# STM32L4R9 register map
File version: 2.2
CPU: CM4 r0p1, little endian, MPU, FPU, 4 interrupt priority bits
Registers are 32-bit, read-write, reset 0x0 unless marked. A register's access mark holds for its fields unless they carry their own. Offsets are from the block's base; [hi:lo] are bit positions; {n}, {i} and the like mark numbered series; 'fields as' and 'values as' point back to an identical list.

## DSI — DSI Host
Base 0x40016C00
0x00 DSI_VR ro reset 0x3133302A — DSI Host Version Register
  [31:0] VERSION — Version of the DSI Host
0x04 DSI_CR — DSI Host Control Register
  [0] EN — Enable
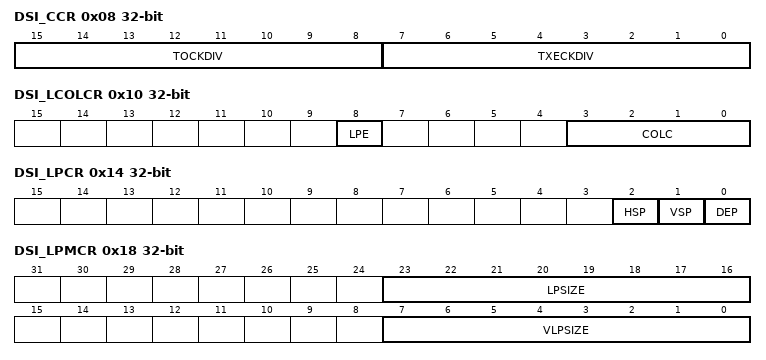
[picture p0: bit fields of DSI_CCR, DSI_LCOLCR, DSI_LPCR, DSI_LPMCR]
0x08 DSI_CCR — DSI HOST Clock Control Register
  [15:8] TOCKDIV — Timeout Clock Division
  [7:0] TXECKDIV — TX Escape Clock Division
0x0C DSI_LVCIDR — DSI Host LTDC VCID Register
  [1:0] VCID — Virtual Channel ID
0x10 DSI_LCOLCR — DSI Host LTDC Color Coding Register
  [8] LPE — Loosely Packet Enable
  [3:0] COLC — Color Coding
0x14 DSI_LPCR — DSI Host LTDC Polarity Configuration Register
  [2] HSP — HSYNC Polarity
  [1] VSP — VSYNC Polarity
  [0] DEP — Data Enable Polarity
0x18 DSI_LPMCR — DSI Host Low-Power mode Configuration Register
  [23:16] LPSIZE — Largest Packet Size
  [7:0] VLPSIZE — VACT Largest Packet Size
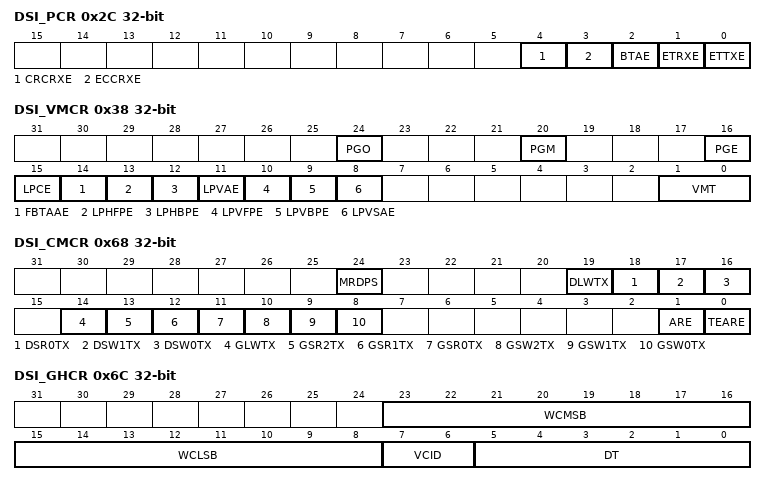
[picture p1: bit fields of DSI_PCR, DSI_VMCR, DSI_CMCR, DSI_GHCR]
0x2C DSI_PCR — DSI Host Protocol Configuration Register
  [4] CRCRXE — CRC Reception Enable
  [3] ECCRXE — ECC Reception Enable
  [2] BTAE — Bus Turn Around Enable
  [1] ETRXE — EoTp Reception Enable
  [0] ETTXE — EoTp Transmission Enable
0x30 DSI_GVCIDR — DSI Host Generic VCID Register
  [1:0] VCID — Virtual Channel ID
0x34 DSI_MCR reset 0x1 — DSI Host mode Configuration Register
  [0] CMDM — Command mode
0x38 DSI_VMCR — DSI Host Video mode Configuration Register
  [24] PGO — Pattern Generator Orientation
  [20] PGM — Pattern Generator mode
  [16] PGE — Pattern Generator Enable
  [15] LPCE — Low-Power Command Enable
  [14] FBTAAE — Frame Bus-Turn-Around Acknowledge Enable
  [13] LPHFPE — Low-Power Horizontal Front-Porch Enable
  [12] LPHBPE — Low-Power Horizontal Back-Porch Enable
  [11] LPVAE — Low-Power Vertical Active Enable
  [10] LPVFPE — Low-power Vertical Front-porch Enable
  [9] LPVBPE — Low-power Vertical Back-Porch Enable
  [8] LPVSAE — Low-Power Vertical Sync Active Enable
  [1:0] VMT — Video mode Type
0x3C DSI_VPCR — DSI Host Video Packet Configuration Register
  [13:0] VPSIZE — Video Packet Size
0x40 DSI_VCCR — DSI Host Video Chunks Configuration Register
  [12:0] NUMC — Number of Chunks
0x44 DSI_VNPCR — DSI Host Video Null Packet Configuration Register
  [12:0] NPSIZE — Null Packet Size
0x48 DSI_VHSACR — DSI Host Video HSA Configuration Register
  [11:0] HSA — Horizontal Synchronism Active duration
0x4C DSI_VHBPCR — DSI Host Video HBP Configuration Register
  [11:0] HBP — Horizontal Back-Porch duration
0x50 DSI_VLCR — DSI Host Video Line Configuration Register
  [14:0] HLINE — Horizontal Line duration
0x54 DSI_VVSACR — DSI Host Video VSA Configuration Register
  [9:0] VSA — Vertical Synchronism Active duration
0x58 DSI_VVBPCR — DSI Host Video VBP Configuration Register
  [9:0] VBP — Vertical Back-Porch duration
0x5C DSI_VVFPCR — DSI Host Video VFP Configuration Register
  [9:0] VFP — Vertical Front-Porch duration
0x60 DSI_VVACR — DSI Host Video VA Configuration Register
  [13:0] VA — Vertical Active duration
0x64 DSI_LCCR — DSI Host LTDC Command Configuration Register
  [15:0] CMDSIZE — Command Size
0x68 DSI_CMCR — DSI Host Command mode Configuration Register
  [24] MRDPS — Maximum Read Packet Size
  [19] DLWTX — DCS Long Write Transmission
  [18] DSR0TX — DCS Short Read Zero parameter Transmission
  [17] DSW1TX — DCS Short Read One parameter Transmission
  [16] DSW0TX — DCS Short Write Zero parameter Transmission
  [14] GLWTX — Generic Long Write Transmission
  [13] GSR2TX — Generic Short Read Two parameters Transmission
  [12] GSR1TX — Generic Short Read One parameters Transmission
  [11] GSR0TX — Generic Short Read Zero parameters Transmission
  [10] GSW2TX — Generic Short Write Two parameters Transmission
  [9] GSW1TX — Generic Short Write One parameters Transmission
  [8] GSW0TX — Generic Short Write Zero parameters Transmission
  [1] ARE — Acknowledge Request Enable
  [0] TEARE — Tearing Effect Acknowledge Request Enable
0x6C DSI_GHCR — DSI Host Generic Header Configuration Register
  [23:16] WCMSB — WordCount MSB
  [15:8] WCLSB — WordCount LSB
  [7:6] VCID — Channel
  [5:0] DT — Type
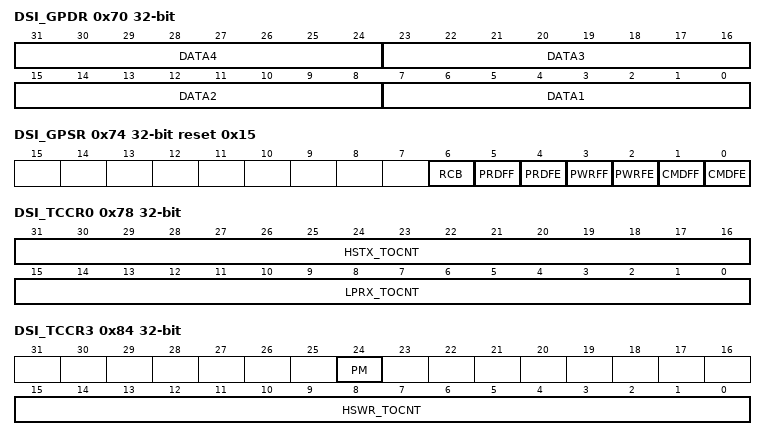
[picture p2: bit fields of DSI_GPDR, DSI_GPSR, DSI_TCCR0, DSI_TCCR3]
0x70 DSI_GPDR — DSI Host Generic Payload Data Register
  [8n-1:8n-8] DATA{n} (n=1..4) — Payload Byte {n}
0x74 DSI_GPSR ro reset 0x15 — DSI Host Generic Packet Status Register
  [6] RCB — Read Command Busy
  [5] PRDFF — Payload Read FIFO Full
  [4] PRDFE — Payload Read FIFO Empty
  [3] PWRFF — Payload Write FIFO Full
  [2] PWRFE — Payload Write FIFO Empty
  [1] CMDFF — Command FIFO Full
  [0] CMDFE — Command FIFO Empty
0x78 DSI_TCCR0 — DSI Host Timeout Counter Configuration Register 0
  [31:16] HSTX_TOCNT — High-Speed Transmission Timeout Counter
  [15:0] LPRX_TOCNT — Low-power Reception Timeout Counter
0x7C DSI_TCCR1 — DSI Host Timeout Counter Configuration Register 1
  [15:0] HSRD_TOCNT — High-Speed Read Timeout Counter
0x80 DSI_TCCR2 — DSI Host Timeout Counter Configuration Register 2
  [15:0] LPRD_TOCNT — Low-Power Read Timeout Counter
0x84 DSI_TCCR3 — DSI Host Timeout Counter Configuration Register 3
  [24] PM — Presp mode
  [15:0] HSWR_TOCNT — High-Speed Write Timeout Counter
0x88 DSI_TCCR4 — DSI Host Timeout Counter Configuration Register 4
  [15:0] LSWR_TOCNT — Low-Power Write Timeout Counter
0x8C DSI_TCCR5 — DSI Host Timeout Counter Configuration Register 5
  [15:0] BTA_TOCNT — Bus-Turn-Around Timeout Counter
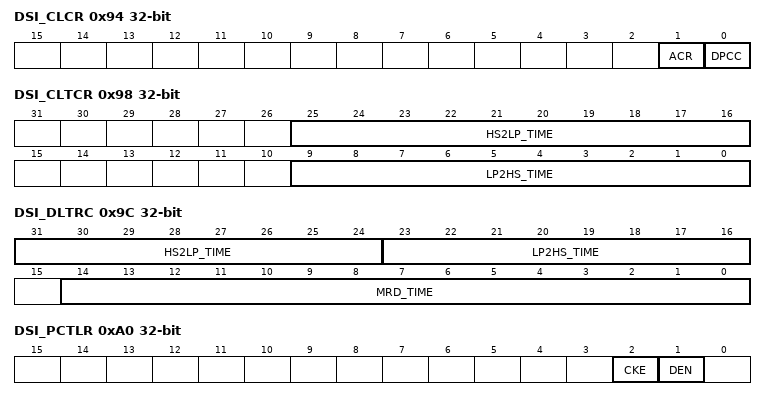
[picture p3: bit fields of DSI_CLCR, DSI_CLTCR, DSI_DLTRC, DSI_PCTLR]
0x94 DSI_CLCR — DSI Host Clock Lane Configuration Register
  [1] ACR — Automatic Clock lane Control
  [0] DPCC — D-PHY Clock Control
0x98 DSI_CLTCR — DSI Host Clock Lane Timer Configuration Register
  [25:16] HS2LP_TIME — High-Speed to Low-Power Time
  [9:0] LP2HS_TIME — Low-Power to High-Speed Time
0x9C DSI_DLTRC — DSI Host Data Lane Timer Configuration Register
  [31:24] HS2LP_TIME — High-Speed To Low-Power Time
  [23:16] LP2HS_TIME — Low-Power To High-Speed Time
  [14:0] MRD_TIME — Maximum Read Time
0xA0 DSI_PCTLR — DSI Host PHY Control Register
  [2] CKE — Clock Enable
  [1] DEN — Digital Enable
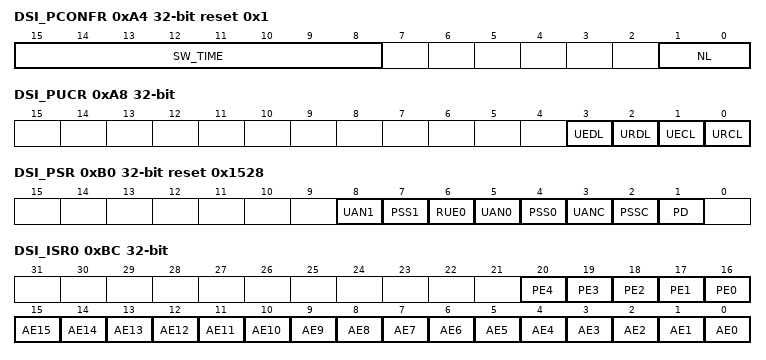
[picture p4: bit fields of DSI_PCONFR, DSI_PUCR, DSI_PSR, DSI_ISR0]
0xA4 DSI_PCONFR reset 0x1 — DSI Host PHY Configuration Register
  [15:8] SW_TIME — Stop Wait Time
  [1:0] NL — Number of Lanes
0xA8 DSI_PUCR — DSI Host PHY ULPS Control Register
  [3] UEDL — ULPS Exit on Data Lane
  [2] URDL — ULPS Request on Data Lane
  [1] UECL — ULPS Exit on Clock Lane
  [0] URCL — ULPS Request on Clock Lane
0xAC DSI_PTTCR — DSI Host PHY TX Triggers Configuration Register
  [3:0] TX_TRIG — Transmission Trigger
0xB0 DSI_PSR ro reset 0x1528 — DSI Host PHY Status Register
  [8] UAN1 — ULPS Active Not lane 1
  [7] PSS1 — PHY Stop State lane 1
  [6] RUE0 — RX ULPS Escape lane 0
  [5] UAN0 — ULPS Active Not lane 1
  [4] PSS0 — PHY Stop State lane 0
  [3] UANC — ULPS Active Not Clock lane
  [2] PSSC — PHY Stop State Clock lane
  [1] PD — PHY Direction
0xBC DSI_ISR0 ro — DSI Host Interrupt & Status Register 0
  [n+16] PE{n} (n=0..4) — PHY Error {n}
  [n] AE{n} (n=0..15) — Acknowledge Error {n}
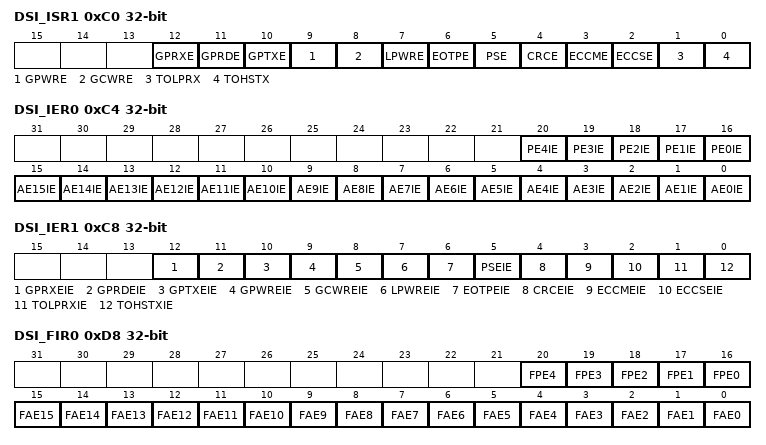
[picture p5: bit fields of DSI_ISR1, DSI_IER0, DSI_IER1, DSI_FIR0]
0xC0 DSI_ISR1 ro — DSI Host Interrupt & Status Register 1
  [12] GPRXE — Generic Payload Receive Error
  [11] GPRDE — Generic Payload Read Error
  [10] GPTXE — Generic Payload Transmit Error
  [9] GPWRE — Generic Payload Write Error
  [8] GCWRE — Generic Command Write Error
  [7] LPWRE — LTDC Payload Write Error
  [6] EOTPE — EoTp Error
  [5] PSE — Packet Size Error
  [4] CRCE — CRC Error
  [3] ECCME — ECC Multi-bit Error
  [2] ECCSE — ECC Single-bit Error
  [1] TOLPRX — Timeout Low-Power Reception
  [0] TOHSTX — Timeout High-Speed Transmission
0xC4 DSI_IER0 — DSI Host Interrupt Enable Register 0
  [n+16] PE{n}IE (n=0..4) — PHY Error {n} Interrupt Enable
  [n] AE{n}IE (n=0..15) — Acknowledge Error {n} Interrupt Enable
0xC8 DSI_IER1 — DSI Host Interrupt Enable Register 1
  [12] GPRXEIE — Generic Payload Receive Error Interrupt Enable
  [11] GPRDEIE — Generic Payload Read Error Interrupt Enable
  [10] GPTXEIE — Generic Payload Transmit Error Interrupt Enable
  [9] GPWREIE — Generic Payload Write Error Interrupt Enable
  [8] GCWREIE — Generic Command Write Error Interrupt Enable
  [7] LPWREIE — LTDC Payload Write Error Interrupt Enable
  [6] EOTPEIE — EoTp Error Interrupt Enable
  [5] PSEIE — Packet Size Error Interrupt Enable
  [4] CRCEIE — CRC Error Interrupt Enable
  [3] ECCMEIE — ECC Multi-bit Error Interrupt Enable
  [2] ECCSEIE — ECC Single-bit Error Interrupt Enable
  [1] TOLPRXIE — Timeout Low-Power Reception Interrupt Enable
  [0] TOHSTXIE — Timeout High-Speed Transmission Interrupt Enable
0xD8 DSI_FIR0 wo — DSI Host Force Interrupt Register 0
  [n+16] FPE{n} (n=0..4) — Force PHY Error {n}
  [n] FAE{n} (n=0..15) — Force Acknowledge Error {n}
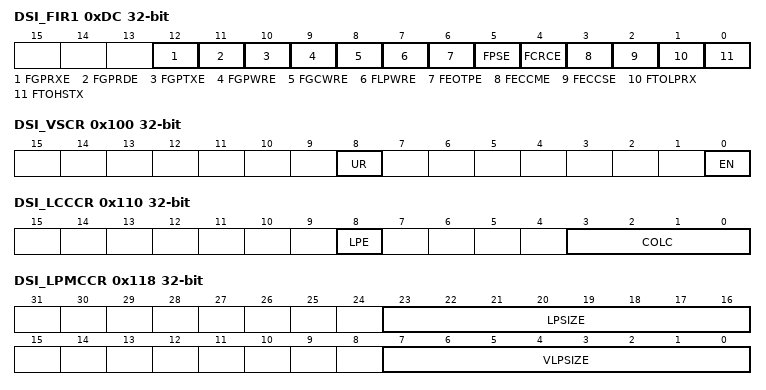
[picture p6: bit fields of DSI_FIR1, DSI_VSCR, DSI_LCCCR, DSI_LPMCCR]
0xDC DSI_FIR1 wo — DSI Host Force Interrupt Register 1
  [12] FGPRXE — Force Generic Payload Receive Error
  [11] FGPRDE — Force Generic Payload Read Error
  [10] FGPTXE — Force Generic Payload Transmit Error
  [9] FGPWRE — Force Generic Payload Write Error
  [8] FGCWRE — Force Generic Command Write Error
  [7] FLPWRE — Force LTDC Payload Write Error
  [6] FEOTPE — Force EoTp Error
  [5] FPSE — Force Packet Size Error
  [4] FCRCE — Force CRC Error
  [3] FECCME — Force ECC Multi-bit Error
  [2] FECCSE — Force ECC Single-bit Error
  [1] FTOLPRX — Force Timeout Low-Power Reception
  [0] FTOHSTX — Force Timeout High-Speed Transmission
0x100 DSI_VSCR — DSI Host Video Shadow Control Register
  [8] UR — Update Register
  [0] EN — Enable
0x10C DSI_LCVCIDR ro — DSI Host LTDC Current VCID Register
  [1:0] VCID — Virtual Channel ID
0x110 DSI_LCCCR ro — DSI Host LTDC Current Color Coding Register
  [8] LPE — Loosely Packed Enable
  [3:0] COLC — Color Coding
0x118 DSI_LPMCCR ro — DSI Host Low-Power mode Current Configuration Register
  fields as DSI_LPMCR
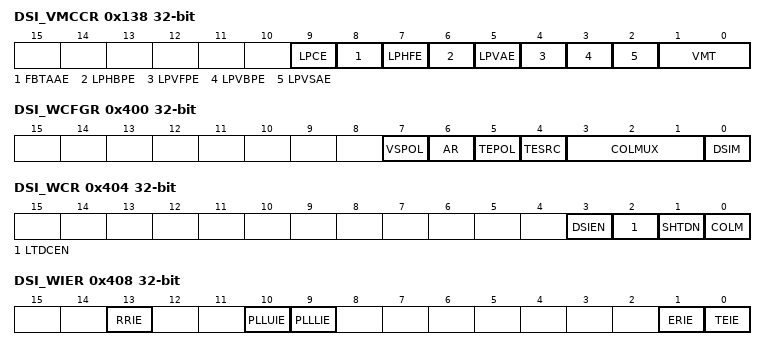
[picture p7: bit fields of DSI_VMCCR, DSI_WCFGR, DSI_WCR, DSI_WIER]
0x138 DSI_VMCCR ro — DSI Host Video mode Current Configuration Register
  [9] LPCE — Low-Power Command Enable
  [8] FBTAAE — Frame BTA Acknowledge Enable
  [7] LPHFE — Low-Power Horizontal Front-Porch Enable
  [6] LPHBPE — Low-power Horizontal Back-Porch Enable
  [5] LPVAE — Low-Power Vertical Active Enable
  [4] LPVFPE — Low-power Vertical Front-Porch Enable
  [3] LPVBPE — Low-power Vertical Back-Porch Enable
  [2] LPVSAE — Low-Power Vertical Sync time Enable
  [1:0] VMT — Video mode Type
0x13C DSI_VPCCR ro — DSI Host Video Packet Current Configuration Register
  [13:0] VPSIZE — Video Packet Size
0x140 DSI_VCCCR ro — DSI Host Video Chunks Current Configuration Register
  [12:0] NUMC — Number of Chunks
0x144 DSI_VNPCCR ro — DSI Host Video Null Packet Current Configuration Register
  [12:0] NPSIZE — Null Packet Size
0x148 DSI_VHSACCR ro — DSI Host Video HSA Current Configuration Register
  [11:0] HSA — Horizontal Synchronism Active duration
0x14C DSI_VHBPCCR ro — DSI Host Video HBP Current Configuration Register
  [11:0] HBP — Horizontal Back-Porch duration
0x150 DSI_VLCCR ro — DSI Host Video Line Current Configuration Register
  [14:0] HLINE — Horizontal Line duration
0x154 DSI_VVSACCR ro — DSI Host Video VSA Current Configuration Register
  [9:0] VSA — Vertical Synchronism Active duration
0x158 DSI_VVBPCCR ro — DSI Host Video VBP Current Configuration Register
  [9:0] VBP — Vertical Back-Porch duration
0x15C DSI_VVFPCCR ro — DSI Host Video VFP Current Configuration Register
  [9:0] VFP — Vertical Front-Porch duration
0x160 DSI_VVACCR ro — DSI Host Video VA Current Configuration Register
  [13:0] VA — Vertical Active duration
0x400 DSI_WCFGR — DSI Wrapper Configuration Register
  [7] VSPOL — VSync Polarity
  [6] AR — Automatic Refresh
  [5] TEPOL — TE Polarity
  [4] TESRC — TE Source
  [3:1] COLMUX — Color Multiplexing
  [0] DSIM — DSI Mode
0x404 DSI_WCR — DSI Wrapper Control Register
  [3] DSIEN — DSI Enable
  [2] LTDCEN — LTDC Enable
  [1] SHTDN — Shutdown
  [0] COLM — Color Mode
0x408 DSI_WIER — DSI Wrapper Interrupt Enable Register
  [13] RRIE — Regulator Ready Interrupt Enable
  [10] PLLUIE — PLL Unlock Interrupt Enable
  [9] PLLLIE — PLL Lock Interrupt Enable
  [1] ERIE — End of Refresh Interrupt Enable
  [0] TEIE — Tearing Effect Interrupt Enable
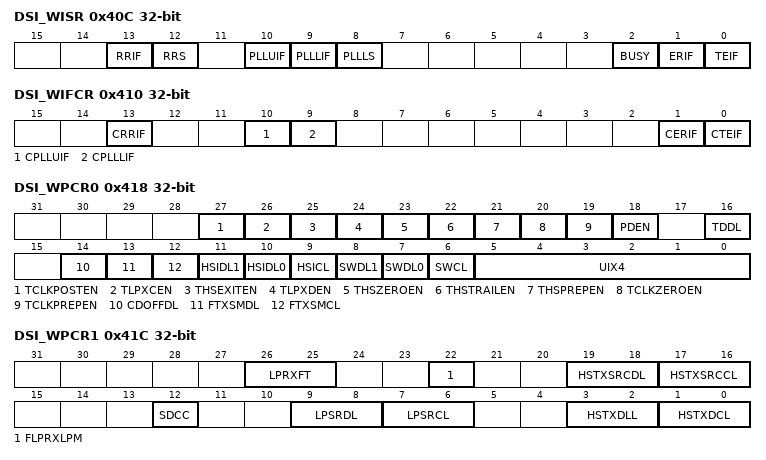
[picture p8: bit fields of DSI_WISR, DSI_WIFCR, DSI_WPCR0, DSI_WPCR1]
0x40C DSI_WISR ro — DSI Wrapper Interrupt & Status Register
  [13] RRIF — Regulator Ready Interrupt Flag
  [12] RRS — Regulator Ready Status
  [10] PLLUIF — PLL Unlock Interrupt Flag
  [9] PLLLIF — PLL Lock Interrupt Flag
  [8] PLLLS — PLL Lock Status
  [2] BUSY — Busy Flag
  [1] ERIF — End of Refresh Interrupt Flag
  [0] TEIF — Tearing Effect Interrupt Flag
0x410 DSI_WIFCR — DSI Wrapper Interrupt Flag Clear Register
  [13] CRRIF — Clear Regulator Ready Interrupt Flag
  [10] CPLLUIF — Clear PLL Unlock Interrupt Flag
  [9] CPLLLIF — Clear PLL Lock Interrupt Flag
  [1] CERIF — Clear End of Refresh Interrupt Flag
  [0] CTEIF — Clear Tearing Effect Interrupt Flag
0x418 DSI_WPCR0 — DSI Wrapper PHY Configuration Register 0
  [27] TCLKPOSTEN — custom time for tCLK-POST Enable
  [26] TLPXCEN — custom time for tLPX for Clock lane Enable
  [25] THSEXITEN — custom time for tHS-EXIT Enable
  [24] TLPXDEN — custom time for tLPX for Data lanes Enable
  [23] THSZEROEN — custom time for tHS-ZERO Enable
  [22] THSTRAILEN — custom time for tHS-TRAIL Enable
  [21] THSPREPEN — custom time for tHS-PREPARE Enable
  [20] TCLKZEROEN — custom time for tCLK-ZERO Enable
  [19] TCLKPREPEN — custom time for tCLK-PREPARE Enable
  [18] PDEN — Pull-Down Enable
  [16] TDDL — Turn Disable Data Lanes
  [14] CDOFFDL — Contention Detection OFF on Data Lanes
  [13] FTXSMDL — Force in TX Stop Mode the Data Lanes
  [12] FTXSMCL — Force in TX Stop Mode the Clock Lane
  [11] HSIDL1 — Invert the High-Speed data signal on Data Lane 1
  [10] HSIDL0 — Invert the Hight-Speed data signal on Data Lane 0
  [9] HSICL — Invert Hight-Speed data signal on Clock Lane
  [8] SWDL1 — Swap Data Lane 1 pins
  [7] SWDL0 — Swap Data Lane 0 pins
  [6] SWCL — Swap Clock Lane pins
  [5:0] UIX4 — Unit Interval multiplied by 4
0x41C DSI_WPCR1 — DSI Wrapper PHY Configuration Register 1
  [26:25] LPRXFT — Low-Power RX low-pass Filtering Tuning
  [22] FLPRXLPM — Forces LP Receiver in Low-Power Mode
  [19:18] HSTXSRCDL — High-Speed Transmission Slew Rate Control on Data Lanes
  [17:16] HSTXSRCCL — High-Speed Transmission Slew Rate Control on Clock Lane
  [12] SDCC — SDD Control
  [9:8] LPSRDL — Low-Power transmission Slew Rate Compensation on Data Lanes
  [7:6] LPSRCL — Low-Power transmission Slew Rate Compensation on Clock Lane
  [3:2] HSTXDLL — High-Speed Transmission Delay on Data Lanes
  [1:0] HSTXDCL — High-Speed Transmission Delay on Clock Lane
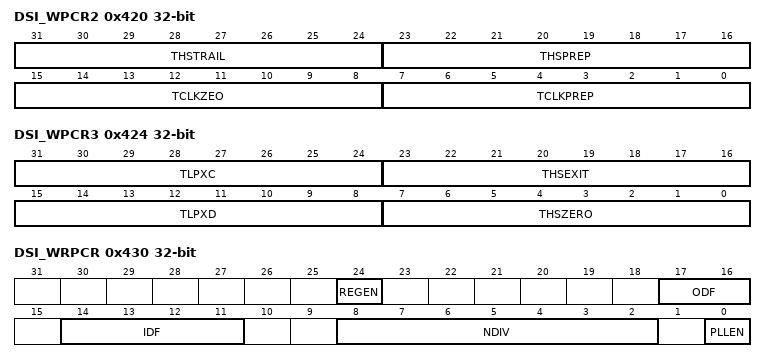
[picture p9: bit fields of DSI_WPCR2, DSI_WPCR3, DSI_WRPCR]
0x420 DSI_WPCR2 — DSI Wrapper PHY Configuration Register 2
  [31:24] THSTRAIL
  [23:16] THSPREP — tHS-PREPARE
  [15:8] TCLKZEO — tCLK-ZERO
  [7:0] TCLKPREP — tCLK-PREPARE
0x424 DSI_WPCR3
  [31:24] TLPXC — tLPXC for Clock lane
  [23:16] THSEXIT
  [15:8] TLPXD — tLPX for Data lanes
  [7:0] THSZERO
0x428 DSI_WPCR4 — DSI Wrapper PHY Configuration Register 4
  [7:0] THSZERO — tCLK-POST
0x430 DSI_WRPCR — DSI Wrapper Regulator and PLL Control Register
  [24] REGEN — Regulator Enable
  [17:16] ODF — PLL Output Division Factor
  [14:11] IDF — PLL Input Division Factor
  [8:2] NDIV — PLL Loop Division Factor
  [0] PLLEN — PLL Enable

## Notices in the file
Copyright (c) 2025 STMicroelectronics.
SPDX-License-Identifier: Apache-2.0
Licensed under the Apache License, Version 2.0 (the "License");
you may not use this file except in compliance with the License.
You may obtain a copy of the License at
http://www.apache.org/licenses/LICENSE-2.0
Unless required by applicable law or agreed to in writing, software
distributed under the License is distributed on an "AS IS" BASIS,
WITHOUT WARRANTIES OR CONDITIONS OF ANY KIND, either express or implied.
See the License for the specific language governing permissions and
limitations under the License.
